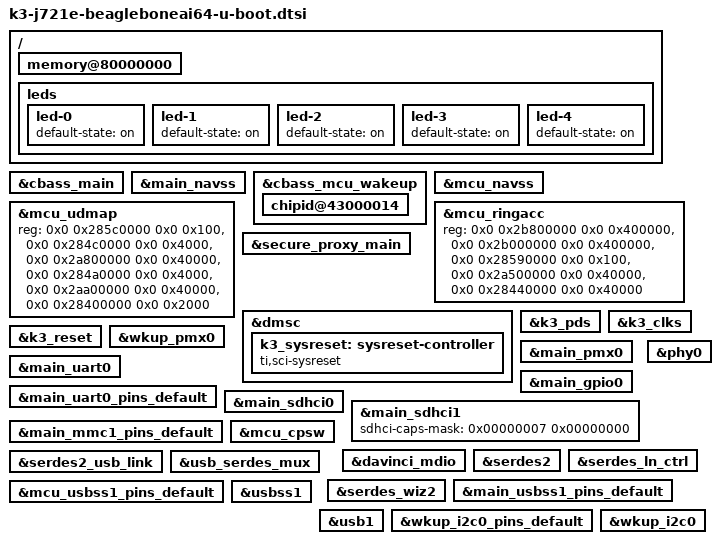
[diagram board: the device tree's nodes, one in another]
// SPDX-License-Identifier: GPL-2.0
/*
 * https://beagleboard.org/ai-64
 *
 * Copyright (C) 2022-2023 Texas Instruments Incorporated - https://www.ti.com/
 * Copyright (C) 2022 Jason Kridner, BeagleBoard.org Foundation
 * Copyright (C) 2022-2023 Robert Nelson, BeagleBoard.org Foundation
 */

/ {
	memory@80000000 {
		bootph-all;
	};

	/* Keep the LEDs on by default to indicate life */
	leds {
		bootph-all;
		led-0 {
			default-state = "on";
			bootph-all;
		};

		led-1 {
			default-state = "on";
			bootph-all;
		};

		led-2 {
			default-state = "on";
			bootph-all;
		};

		led-3 {
			default-state = "on";
			bootph-all;
		};

		led-4 {
			default-state = "on";
			bootph-all;
		};
	};
};

&cbass_main {
	bootph-all;
};

&main_navss {
	bootph-all;
};

&cbass_mcu_wakeup {
	bootph-all;

	chipid@43000014 {
		bootph-all;
	};
};

&mcu_navss {
	bootph-all;
};

&mcu_ringacc {
	reg = <0x0 0x2b800000 0x0 0x400000>,
		<0x0 0x2b000000 0x0 0x400000>,
		<0x0 0x28590000 0x0 0x100>,
		<0x0 0x2a500000 0x0 0x40000>,
		<0x0 0x28440000 0x0 0x40000>;
	reg-names = "rt", "fifos", "proxy_gcfg", "proxy_target", "cfg";
	bootph-all;
};

&mcu_udmap {
	reg = <0x0 0x285c0000 0x0 0x100>,
		<0x0 0x284c0000 0x0 0x4000>,
		<0x0 0x2a800000 0x0 0x40000>,
		<0x0 0x284a0000 0x0 0x4000>,
		<0x0 0x2aa00000 0x0 0x40000>,
		<0x0 0x28400000 0x0 0x2000>;
	reg-names = "gcfg", "rchan", "rchanrt", "tchan",
		"tchanrt", "rflow";
	bootph-all;
};

&secure_proxy_main {
	bootph-all;
};

&dmsc {
	bootph-all;
	k3_sysreset: sysreset-controller {
		compatible = "ti,sci-sysreset";
		bootph-all;
	};
};

&k3_pds {
	bootph-all;
};

&k3_clks {
	bootph-all;
};

&k3_reset {
	bootph-all;
};

&wkup_pmx0 {
	bootph-all;
};

&main_pmx0 {
	bootph-all;
};

&main_uart0 {
	bootph-all;
};

&main_gpio0 {
	bootph-all;
};

&main_uart0_pins_default {
	bootph-all;
};

&main_sdhci0 {
	bootph-all;
};

&main_sdhci1 {
	bootph-all;
	sdhci-caps-mask = <0x00000007 0x00000000>;
	/delete-property/ cd-gpios;
	/delete-property/ cd-debounce-delay-ms;
	/delete-property/ ti,fails-without-test-cd;
	/delete-property/ no-1-8-v;
};

&main_mmc1_pins_default {
	bootph-all;
};

&mcu_cpsw {
	bootph-all;
};

&davinci_mdio {
	bootph-all;
};

&phy0 {
	bootph-all;
};

&serdes2 {
	bootph-all;
};

&serdes_ln_ctrl {
	bootph-all;
};

&serdes2_usb_link {
	bootph-all;
};

&usb_serdes_mux {
	bootph-all;
};

&serdes_wiz2 {
	bootph-all;
};

&main_usbss1_pins_default {
	bootph-all;
};

&mcu_usbss1_pins_default {
	bootph-all;
};

&usbss1 {
	bootph-all;
};

&usb1 {
	bootph-all;
};

&wkup_i2c0_pins_default {
	bootph-all;
};

&wkup_i2c0 {
	bootph-all;
};

#define SPL_J721E_EVM_DTB "spl/dts/k3-j721e-beagleboneai64.dtb"
#define J721E_EVM_DTB "arch/arm/dts/k3-j721e-beagleboneai64.dtb"
#include "k3-j721e-binman.dtsi"
